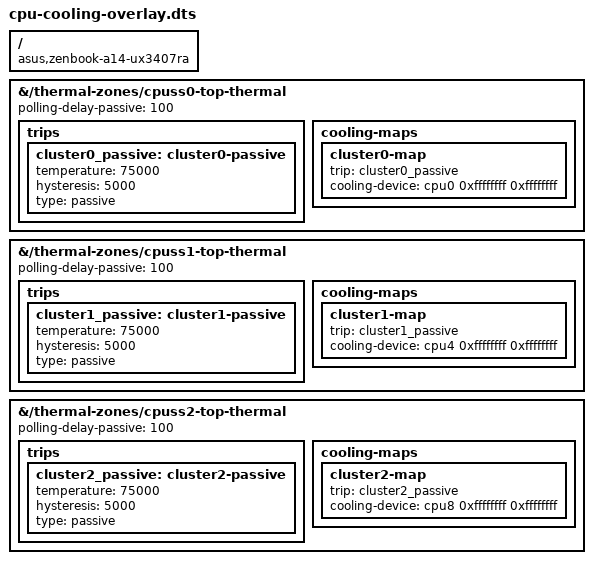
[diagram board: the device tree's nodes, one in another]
/dts-v1/;
/plugin/;

/*
 * Issue 23: CPU thermal cooling-maps overlay for X1E80100 (Snapdragon X Elite).
 *
 * The upstream x1e80100.dtsi defines 6 per-cluster CPU thermal zones but none
 * have cooling-maps or passive trip points. The only trip is "critical" at
 * 115 C which triggers an emergency kernel shutdown — there is no intermediate
 * throttling step. Combined with the absence of LMH device-tree nodes and
 * SCMI powercap zones, the CPU can draw enough sustained current under
 * all-core load to trip the PMIC overcurrent protection, causing an instant
 * hard reset.
 *
 * This overlay adds to each CPU cluster thermal zone:
 *   - A "passive" trip point at 75 C
 *   - A cooling-map binding the cluster's cpufreq cooling device to that trip
 *   - polling-delay-passive of 100 ms for responsive throttling
 *
 * The cpufreq cooling devices already exist because every cpu node in the base
 * DTS carries #cooling-cells = <2>. This overlay simply wires them into the
 * thermal framework so the step_wise governor can throttle frequency.
 *
 * Trip point temperatures (tunable):
 *   75 C passive  — begin frequency throttling (step_wise governor)
 *   115 C critical — emergency shutdown (existing, unchanged)
 *
 * At idle the CPU sits at ~27 C and the PMIC at ~37 C. Under all-core stress
 * the PMIC OCP trips after ~60 s even at 1.92 GHz. A 75 C passive point
 * catches sustained load while leaving headroom for burst workloads.
 *
 * Note: THERMAL_NO_LIMIT = 0xffffffff (from dt-bindings/thermal/thermal.h).
 * We use the raw value because NixOS compiles DT overlays with dtc directly
 * (no C preprocessor for #include).
 *
 * Compatible is restricted to the ASUS Zenbook A14 only — other hamoa boards
 * (Lenovo IdeaCentre, IoT EVKs) may lack the __symbols__ entries needed to
 * resolve &cpu0/&cpu4/&cpu8 phandle references at overlay apply time.
 */

/ {
    compatible = "asus,zenbook-a14-ux3407ra";

    /* Cluster 0 (CPUs 0-3): cpuss0-top-thermal */
    fragment@1 {
        target-path = "/thermal-zones/cpuss0-top-thermal";
        __overlay__ {
            polling-delay-passive = <100>;

            trips {
                cluster0_passive: cluster0-passive {
                    temperature = <75000>;
                    hysteresis = <5000>;
                    type = "passive";
                };
            };

            cooling-maps {
                cluster0-map {
                    trip = <&cluster0_passive>;
                    cooling-device = <&cpu0 0xffffffff 0xffffffff>;
                };
            };
        };
    };

    /* Cluster 1 (CPUs 4-7): cpuss1-top-thermal */
    fragment@2 {
        target-path = "/thermal-zones/cpuss1-top-thermal";
        __overlay__ {
            polling-delay-passive = <100>;

            trips {
                cluster1_passive: cluster1-passive {
                    temperature = <75000>;
                    hysteresis = <5000>;
                    type = "passive";
                };
            };

            cooling-maps {
                cluster1-map {
                    trip = <&cluster1_passive>;
                    cooling-device = <&cpu4 0xffffffff 0xffffffff>;
                };
            };
        };
    };

    /* Cluster 2 (CPUs 8-11): cpuss2-top-thermal */
    fragment@3 {
        target-path = "/thermal-zones/cpuss2-top-thermal";
        __overlay__ {
            polling-delay-passive = <100>;

            trips {
                cluster2_passive: cluster2-passive {
                    temperature = <75000>;
                    hysteresis = <5000>;
                    type = "passive";
                };
            };

            cooling-maps {
                cluster2-map {
                    trip = <&cluster2_passive>;
                    cooling-device = <&cpu8 0xffffffff 0xffffffff>;
                };
            };
        };
    };
};
